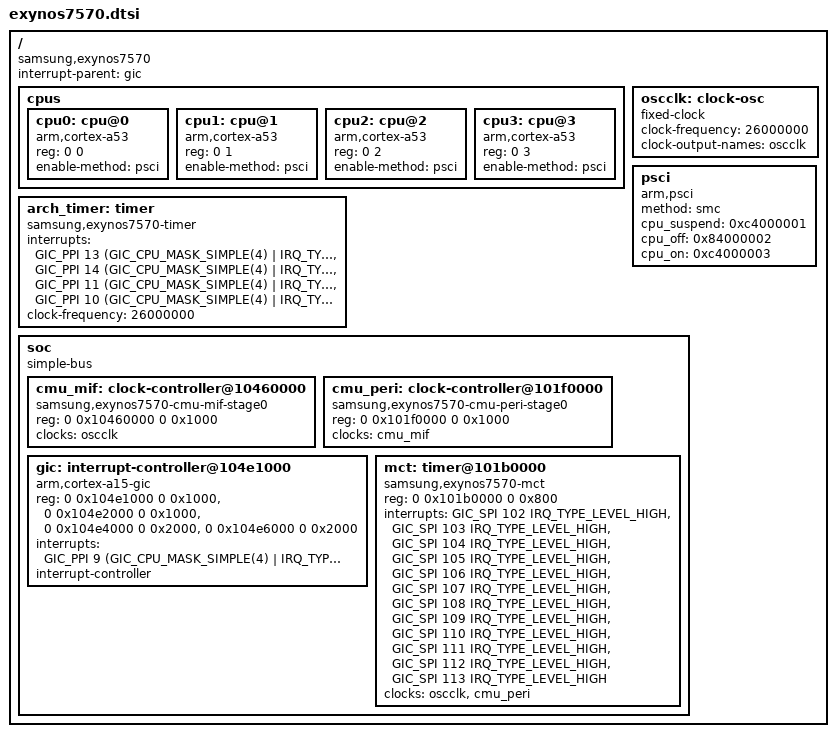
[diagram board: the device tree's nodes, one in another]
// SPDX-License-Identifier: GPL-2.0-only
/* Independently written minimal Exynos7570 description for stage0. */

#include <dt-bindings/interrupt-controller/arm-gic.h>

/ {
	compatible = "samsung,exynos7570";
	#address-cells = <2>;
	#size-cells = <2>;
	interrupt-parent = <&gic>;

	cpus {
		#address-cells = <2>;
		#size-cells = <0>;

		cpu0: cpu@0 {
			device_type = "cpu";
			compatible = "arm,cortex-a53";
			reg = <0 0>;
			enable-method = "psci";
		};

		cpu1: cpu@1 {
			device_type = "cpu";
			compatible = "arm,cortex-a53";
			reg = <0 1>;
			enable-method = "psci";
		};

		cpu2: cpu@2 {
			device_type = "cpu";
			compatible = "arm,cortex-a53";
			reg = <0 2>;
			enable-method = "psci";
		};

		cpu3: cpu@3 {
			device_type = "cpu";
			compatible = "arm,cortex-a53";
			reg = <0 3>;
			enable-method = "psci";
		};
	};

	oscclk: clock-osc {
		compatible = "fixed-clock";
		#clock-cells = <0>;
		clock-frequency = <26000000>;
		clock-output-names = "oscclk";
	};

	psci {
		compatible = "arm,psci";
		method = "smc";
		cpu_suspend = <0xc4000001>;
		cpu_off = <0x84000002>;
		cpu_on = <0xc4000003>;
	};

	arch_timer: timer {
		compatible = "samsung,exynos7570-timer", "arm,armv8-timer";
		interrupts = <GIC_PPI 13 (GIC_CPU_MASK_SIMPLE(4) | IRQ_TYPE_LEVEL_LOW)>,
			     <GIC_PPI 14 (GIC_CPU_MASK_SIMPLE(4) | IRQ_TYPE_LEVEL_LOW)>,
			     <GIC_PPI 11 (GIC_CPU_MASK_SIMPLE(4) | IRQ_TYPE_LEVEL_LOW)>,
			     <GIC_PPI 10 (GIC_CPU_MASK_SIMPLE(4) | IRQ_TYPE_LEVEL_LOW)>;
		/* Do not rely on stock firmware to initialize CNTFRQ correctly. */
		clock-frequency = <26000000>;
	};

	soc {
		compatible = "simple-bus";
		#address-cells = <2>;
		#size-cells = <2>;
		ranges;

		cmu_mif: clock-controller@10460000 {
			compatible = "samsung,exynos7570-cmu-mif-stage0";
			reg = <0 0x10460000 0 0x1000>;
			clocks = <&oscclk>;
			clock-names = "oscclk";
			#clock-cells = <0>;
		};

		cmu_peri: clock-controller@101f0000 {
			compatible = "samsung,exynos7570-cmu-peri-stage0";
			reg = <0 0x101f0000 0 0x1000>;
			clocks = <&cmu_mif>;
			clock-names = "peri-bus";
			#clock-cells = <0>;
		};

		gic: interrupt-controller@104e1000 {
			compatible = "arm,cortex-a15-gic";
			reg = <0 0x104e1000 0 0x1000>,
			      <0 0x104e2000 0 0x1000>,
			      <0 0x104e4000 0 0x2000>,
			      <0 0x104e6000 0 0x2000>;
			interrupts = <GIC_PPI 9 (GIC_CPU_MASK_SIMPLE(4) | IRQ_TYPE_LEVEL_HIGH)>;
			interrupt-controller;
			#address-cells = <0>;
			#interrupt-cells = <3>;
		};

		mct: timer@101b0000 {
			compatible = "samsung,exynos7570-mct", "samsung,exynos4210-mct";
			reg = <0 0x101b0000 0 0x800>;
			interrupts = <GIC_SPI 102 IRQ_TYPE_LEVEL_HIGH>,
				     <GIC_SPI 103 IRQ_TYPE_LEVEL_HIGH>,
				     <GIC_SPI 104 IRQ_TYPE_LEVEL_HIGH>,
				     <GIC_SPI 105 IRQ_TYPE_LEVEL_HIGH>,
				     <GIC_SPI 106 IRQ_TYPE_LEVEL_HIGH>,
				     <GIC_SPI 107 IRQ_TYPE_LEVEL_HIGH>,
				     <GIC_SPI 108 IRQ_TYPE_LEVEL_HIGH>,
				     <GIC_SPI 109 IRQ_TYPE_LEVEL_HIGH>,
				     <GIC_SPI 110 IRQ_TYPE_LEVEL_HIGH>,
				     <GIC_SPI 111 IRQ_TYPE_LEVEL_HIGH>,
				     <GIC_SPI 112 IRQ_TYPE_LEVEL_HIGH>,
				     <GIC_SPI 113 IRQ_TYPE_LEVEL_HIGH>;
			/* Tick input and managed PCLK gate are different clocks. */
			clocks = <&oscclk>, <&cmu_peri>;
			clock-names = "fin_pll", "mct";
		};
	};
};
